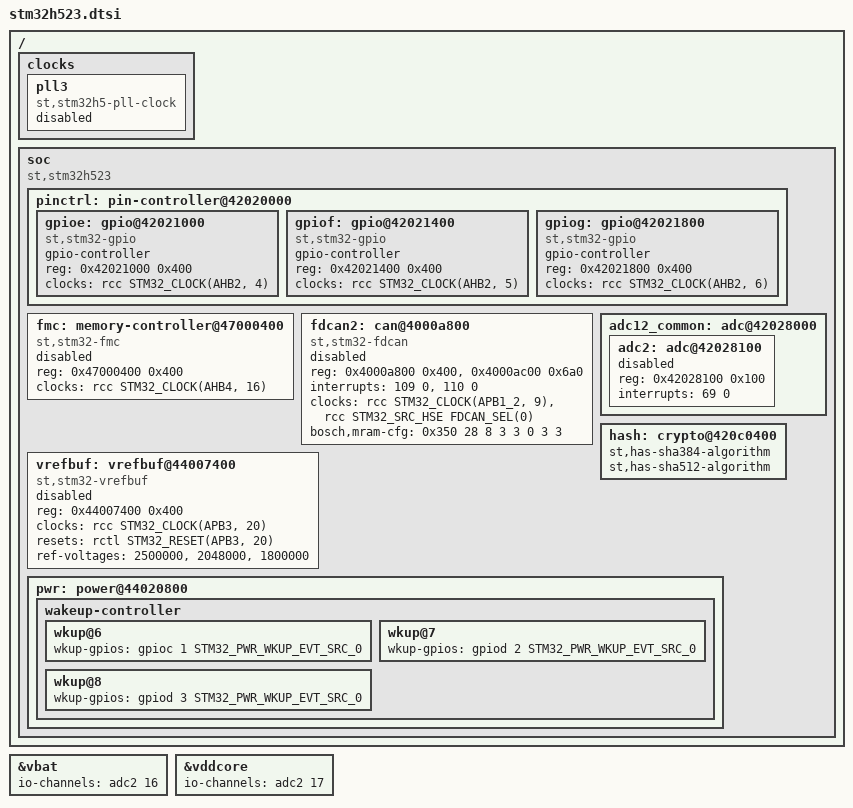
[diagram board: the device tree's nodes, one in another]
/*
 * Copyright (c) 2024 STMicroelectronics
 * Copyright (c) 2025 Filip Stojanovic
 * Copyright (c) 2026 STMicroelectronics
 *
 * SPDX-License-Identifier: Apache-2.0
 */
#include <st/h5/stm32h5.dtsi>

/ {
	clocks {
		pll3: pll3 {
			#clock-cells = <0>;
			compatible = "st,stm32h5-pll-clock";
			status = "disabled";
		};
	};

	soc {
		compatible = "st,stm32h523", "st,stm32h5", "simple-bus";

		pinctrl: pin-controller@42020000 {
			gpioe: gpio@42021000 {
				compatible = "st,stm32-gpio";
				gpio-controller;
				#gpio-cells = <2>;
				reg = <0x42021000 0x400>;
				clocks = <&rcc STM32_CLOCK(AHB2, 4)>;
			};

			gpiof: gpio@42021400 {
				compatible = "st,stm32-gpio";
				gpio-controller;
				#gpio-cells = <2>;
				reg = <0x42021400 0x400>;
				clocks = <&rcc STM32_CLOCK(AHB2, 5)>;
			};

			gpiog: gpio@42021800 {
				compatible = "st,stm32-gpio";
				gpio-controller;
				#gpio-cells = <2>;
				reg = <0x42021800 0x400>;
				clocks = <&rcc STM32_CLOCK(AHB2, 6)>;
			};
		};

		fmc: memory-controller@47000400 {
			compatible = "st,stm32-fmc";
			reg = <0x47000400 0x400>;
			clocks = <&rcc STM32_CLOCK(AHB4, 16)>;
			status = "disabled";
		};

		fdcan2: can@4000a800 {
			compatible = "st,stm32-fdcan";
			reg = <0x4000a800 0x400>, <0x4000ac00 0x6a0>;
			reg-names = "m_can", "message_ram";
			interrupts = <109 0>, <110 0>;
			interrupt-names = "int0", "int1";
			/* common clock FDCAN 1 & 2 */
			clocks = <&rcc STM32_CLOCK(APB1_2, 9)>,
				 <&rcc STM32_SRC_HSE FDCAN_SEL(0)>;
			bosch,mram-cfg = <0x350 28 8 3 3 0 3 3>;
			status = "disabled";
		};

		vrefbuf: vrefbuf@44007400 {
			compatible = "st,stm32-vrefbuf";
			reg = <0x44007400 0x400>;
			clocks = <&rcc STM32_CLOCK(APB3, 20)>;
			resets = <&rctl STM32_RESET(APB3, 20)>;
			ref-voltages = <2500000>, <2048000>, <1800000>;
			status = "disabled";
		};

		adc12_common: adc@42028000 {
			adc2: adc@42028100 {
				reg = <0x42028100 0x100>;
				interrupts = <69 0>;
				#io-channel-cells = <1>;
				status = "disabled";
			};
		};

		hash: crypto@420c0400 {
			st,has-sha384-algorithm;
			st,has-sha512-algorithm;
		};

		pwr: power@44020800 {
			wakeup-controller {
				wkup@6 {
					wkup-gpios = <&gpioc 1 STM32_PWR_WKUP_EVT_SRC_0>;
				};

				wkup@7 {
					wkup-gpios = <&gpiod 2 STM32_PWR_WKUP_EVT_SRC_0>;
				};

				wkup@8 {
					wkup-gpios = <&gpiod 3 STM32_PWR_WKUP_EVT_SRC_0>;
				};
			};
		};
	};
};

&vbat {
	io-channels = <&adc2 16>;
};

&vddcore {
	io-channels = <&adc2 17>;
};
